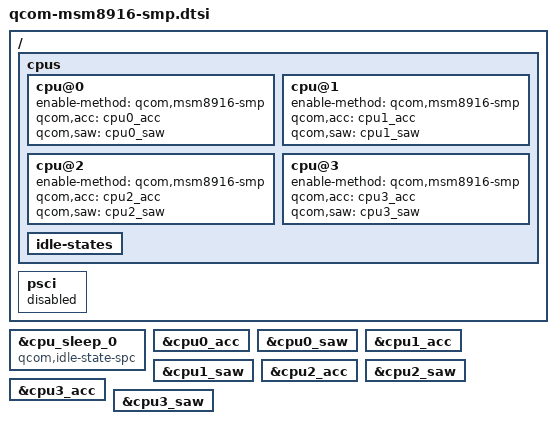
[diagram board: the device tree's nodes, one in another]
// SPDX-License-Identifier: GPL-2.0-only

/ {
	cpus {
		cpu@0 {
			enable-method = "qcom,msm8916-smp";
			qcom,acc = <&cpu0_acc>;
			qcom,saw = <&cpu0_saw>;
		};
		cpu@1 {
			enable-method = "qcom,msm8916-smp";
			qcom,acc = <&cpu1_acc>;
			qcom,saw = <&cpu1_saw>;
		};
		cpu@2 {
			enable-method = "qcom,msm8916-smp";
			qcom,acc = <&cpu2_acc>;
			qcom,saw = <&cpu2_saw>;
		};
		cpu@3 {
			enable-method = "qcom,msm8916-smp";
			qcom,acc = <&cpu3_acc>;
			qcom,saw = <&cpu3_saw>;
		};

		idle-states {
			/delete-property/ entry-method;
		};
	};

	psci {
		status = "disabled";
	};
};

&cpu_sleep_0 {
	compatible = "qcom,idle-state-spc", "arm,idle-state";
};

&cpu0_acc {
	status = "okay";
};

&cpu0_saw {
	status = "okay";
};

&cpu1_acc {
	status = "okay";
};

&cpu1_saw {
	status = "okay";
};

&cpu2_acc {
	status = "okay";
};

&cpu2_saw {
	status = "okay";
};

&cpu3_acc {
	status = "okay";
};

&cpu3_saw {
	status = "okay";
};
